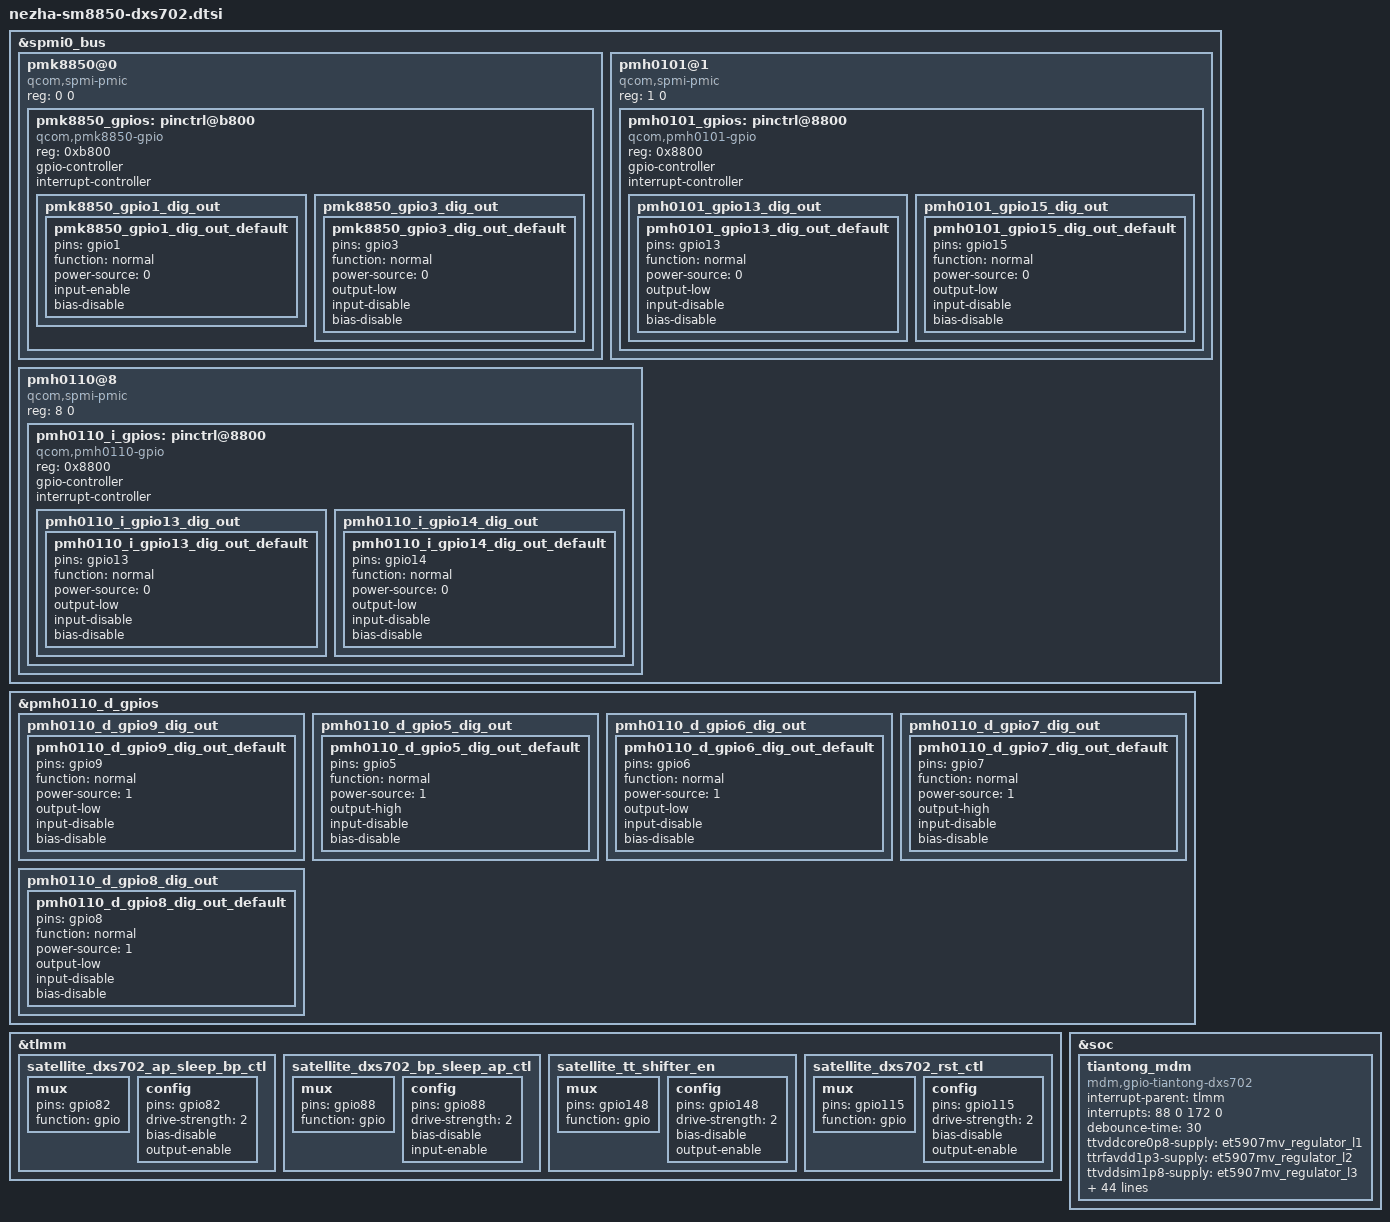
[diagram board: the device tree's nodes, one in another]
// SPDX-License-Identifier: GPL-2.0-only
/* Xiaomi 17 Ultra satellite modem wiring. */

&spmi0_bus {
	#address-cells = <2>;
	#size-cells = <0>;

	pmk8850@0 {
		compatible = "qcom,spmi-pmic";
		reg = <0 0>;
		#address-cells = <1>;
		#size-cells = <0>;

		pmk8850_gpios: pinctrl@b800 {
			compatible = "qcom,pmk8850-gpio";
			reg = <0xb800>;
			gpio-controller;
			#gpio-cells = <2>;
			interrupt-controller;
			#interrupt-cells = <2>;
		};
	};

	pmh0101@1 {
		compatible = "qcom,spmi-pmic";
		reg = <1 0>;
		#address-cells = <1>;
		#size-cells = <0>;

		pmh0101_gpios: pinctrl@8800 {
			compatible = "qcom,pmh0101-gpio";
			reg = <0x8800>;
			gpio-controller;
			#gpio-cells = <2>;
			interrupt-controller;
			#interrupt-cells = <2>;
		};
	};

	pmh0110@8 {
		compatible = "qcom,spmi-pmic";
		reg = <8 0>;
		#address-cells = <1>;
		#size-cells = <0>;

		pmh0110_i_gpios: pinctrl@8800 {
			compatible = "qcom,pmh0110-gpio";
			reg = <0x8800>;
			gpio-controller;
			#gpio-cells = <2>;
			interrupt-controller;
			#interrupt-cells = <2>;
		};
	};
};

&pmk8850_gpios {
	pmk8850_gpio1_dig_out {
		pmk8850_gpio1_dig_out_default: pmk8850_gpio1_dig_out_default {
			pins = "gpio1";
			function = "normal";
			power-source = <0>;
			input-enable;
			bias-disable;
		};
	};

	pmk8850_gpio3_dig_out {
		pmk8850_gpio3_dig_out_default: pmk8850_gpio3_dig_out_default {
			pins = "gpio3";
			function = "normal";
			power-source = <0>;
			output-low;
			input-disable;
			bias-disable;
		};
	};
};

&pmh0101_gpios {
	pmh0101_gpio13_dig_out {
		pmh0101_gpio13_dig_out_default: pmh0101_gpio13_dig_out_default {
			pins = "gpio13";
			function = "normal";
			power-source = <0>;
			output-low;
			input-disable;
			bias-disable;
		};
	};

	pmh0101_gpio15_dig_out {
		pmh0101_gpio15_dig_out_default: pmh0101_gpio15_dig_out_default {
			pins = "gpio15";
			function = "normal";
			power-source = <0>;
			output-low;
			input-disable;
			bias-disable;
		};
	};
};

&pmh0110_d_gpios {
	pmh0110_d_gpio9_dig_out {
		pmh0110_d_gpio9_dig_out_default: pmh0110_d_gpio9_dig_out_default {
			pins = "gpio9";
			function = "normal";
			power-source = <1>;
			output-low;
			input-disable;
			bias-disable;
		};
	};

	pmh0110_d_gpio5_dig_out {
		pmh0110_d_gpio5_dig_out_default: pmh0110_d_gpio5_dig_out_default {
			pins = "gpio5";
			function = "normal";
			power-source = <1>;
			output-high;
			input-disable;
			bias-disable;
		};
	};

	pmh0110_d_gpio6_dig_out {
		pmh0110_d_gpio6_dig_out_default: pmh0110_d_gpio6_dig_out_default {
			pins = "gpio6";
			function = "normal";
			power-source = <1>;
			output-low;
			input-disable;
			bias-disable;
		};
	};

	pmh0110_d_gpio7_dig_out {
		pmh0110_d_gpio7_dig_out_default: pmh0110_d_gpio7_dig_out_default {
			pins = "gpio7";
			function = "normal";
			power-source = <1>;
			output-high;
			input-disable;
			bias-disable;
		};
	};

	pmh0110_d_gpio8_dig_out {
		pmh0110_d_gpio8_dig_out_default: pmh0110_d_gpio8_dig_out_default {
			pins = "gpio8";
			function = "normal";
			power-source = <1>;
			output-low;
			input-disable;
			bias-disable;
		};
	};
};

&pmh0110_i_gpios {
	pmh0110_i_gpio13_dig_out {
		pmh0110_i_gpio13_dig_out_default: pmh0110_i_gpio13_dig_out_default {
			pins = "gpio13";
			function = "normal";
			power-source = <0>;
			output-low;
			input-disable;
			bias-disable;
		};
	};

	pmh0110_i_gpio14_dig_out {
		pmh0110_i_gpio14_dig_out_default: pmh0110_i_gpio14_dig_out_default {
			pins = "gpio14";
			function = "normal";
			power-source = <0>;
			output-low;
			input-disable;
			bias-disable;
		};
	};
};

&tlmm {
	satellite_dxs702_ap_sleep_bp_ctl: satellite_dxs702_ap_sleep_bp_ctl {
		mux {
			pins = "gpio82";
			function = "gpio";
		};
		config {
			pins = "gpio82";
			drive-strength = <2>;
			bias-disable;
			output-enable;
		};
	};

	satellite_dxs702_bp_sleep_ap_ctl: satellite_dxs702_bp_sleep_ap_ctl {
		mux {
			pins = "gpio88";
			function = "gpio";
		};
		config {
			pins = "gpio88";
			drive-strength = <2>;
			bias-disable;
			input-enable;
		};
	};

	satellite_tt_shifter_en: satellite_tt_shifter_en {
		mux {
			pins = "gpio148";
			function = "gpio";
		};
		config {
			pins = "gpio148";
			drive-strength = <2>;
			bias-disable;
			output-enable;
		};
	};

	satellite_dxs702_rst_ctl: satellite_dxs702_rst_ctl {
		mux {
			pins = "gpio115";
			function = "gpio";
		};
		config {
			pins = "gpio115";
			drive-strength = <2>;
			bias-disable;
			output-enable;
		};
	};
};

&soc {
	tiantong_mdm {
		compatible = "mdm,gpio-tiantong-dxs702";
		interrupt-parent = <&tlmm>;
		interrupts = <88 0 172 0>;
		debounce-time = <30>;
		ttvddcore0p8-supply = <&et5907mv_regulator_l1>;
		ttrfavdd1p3-supply = <&et5907mv_regulator_l2>;
		ttvddsim1p8-supply = <&et5907mv_regulator_l3>;
		ttlna2p8-supply = <&et5907mv_regulator_l4>;
		ttvddio1p8-supply = <&et5907mv_regulator_l5>;
		ttvccflash1p8-supply = <&et5907mv_regulator_l6>;
		ttrf1p8-supply = <&et5907mv_regulator_l7>;
		ttdcdcpavcc4p6-supply = <&hl7603_regulator_l1>;
		gpio-ap-sleep-bp = <&tlmm 82 0>;
		gpio-bp-sleep-ap = <&tlmm 88 0>;
		gpio-ap-status-bp = <&pmk8850_gpios 3 1>;
		gpio-bp-status-ap = <&pmk8850_gpios 1 1>;
		gpio-bbic-rst = <&tlmm 115 0>;
		gpio-pmic-rst = <&tlmm 160 0>;
		gpio-pmic-irq = <&tlmm 172 0>;
		gpio-tt-shifter-en = <&tlmm 148 0>;
		gpio-boot-mode1 = <&pmh0101_gpios 13 1>;
		gpio-ls-boot-sel = <&pmh0110_d_gpios 9 1>;
		gpio-sat-rxfem-c0 = <&pmh0110_d_gpios 14 1>;
		gpio-xw-safeic-en = <&pmh0101_gpios 14 1>;
		gpio-tt-vddio-1p8-en = <&pmh0101_gpios 15 1>;
		gpio-uim-ls-tt-en = <&pmh0101_gpios 16 1>;
		gpio-uim1-ls-en = <&pmh0101_gpios 8 1>;
		gpio-uim2-ls-en = <&pmh0101_gpios 10 1>;
		gpio-vdd-sim1-qc-en = <&pmh0110_d_gpios 5 1>;
		gpio-vdd-sim1-tt-en = <&pmh0110_d_gpios 6 1>;
		gpio-vdd-sim2-qc-en = <&pmh0110_d_gpios 7 1>;
		gpio-vdd-sim2-tt-en = <&pmh0110_d_gpios 8 1>;
		gpio-sim-switch1-en = <&pmh0110_i_gpios 13 1>;
		gpio-sim-switch2-en = <&pmh0110_i_gpios 14 1>;
		gpio-tt-bd-sel = <&pmh0110_d_gpios 13 1>;
		gpio-ttprx-lna-ldo-en = <&pmh0101_gpios 18 1>;
		pinctrl-names = "default";
		pinctrl-0 = <&satellite_dxs702_ap_sleep_bp_ctl
			     &satellite_dxs702_bp_sleep_ap_ctl
			     &pmk8850_gpio1_dig_out_default
			     &pmk8850_gpio3_dig_out_default
			     &satellite_tt_shifter_en
			     &satellite_dxs702_rst_ctl
			     &pmh0101_gpio13_dig_out_default
			     &pmh0101_gpio15_dig_out_default
			     &pmh0110_d_gpio9_dig_out_default
			     &pmh0110_d_gpio5_dig_out_default
			     &pmh0110_d_gpio6_dig_out_default
			     &pmh0110_d_gpio7_dig_out_default
			     &pmh0110_d_gpio8_dig_out_default
			     &pmh0110_i_gpio13_dig_out_default
			     &pmh0110_i_gpio14_dig_out_default>;
	};
};
